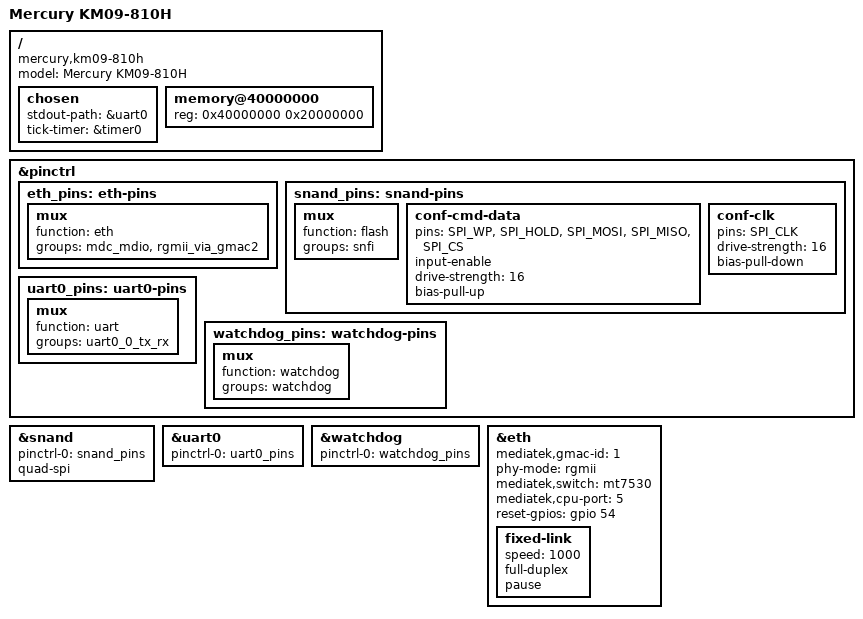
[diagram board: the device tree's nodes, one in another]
// SPDX-License-Identifier: GPL-2.0
/*
 * U-Boot device tree for the Mercury KM09-810H.
 * Configured with GMAC1 connected to internal MT7530 switch via RGMII (port@5 = CPU),
 * matching the stock bootloader ("GMAC1 Force link status enable" / "MT7530 Reset Completed").
 * GMAC0 is the WAN port behind an Aquantia PHY (2500base-x) and is NOT used here.
 */

/dts-v1/;
#include "mt7622.dtsi"
#include "mt7622-u-boot.dtsi"

/ {
	#address-cells = <1>;
	#size-cells = <1>;
	model = "Mercury KM09-810H";
	compatible = "mercury,km09-810h", "mediatek,mt7622";

	chosen {
		stdout-path = &uart0;
		tick-timer = &timer0;
	};

	memory@40000000 {
		device_type = "memory";
		reg = <0x40000000 0x20000000>;
	};
};

&pinctrl {
	eth_pins: eth-pins {
		mux {
			function = "eth";
			groups = "mdc_mdio", "rgmii_via_gmac2";
		};
	};

	snand_pins: snand-pins {
		mux {
			function = "flash";
			groups = "snfi";
		};

		conf-cmd-data {
			pins = "SPI_WP", "SPI_HOLD", "SPI_MOSI",
			       "SPI_MISO", "SPI_CS";
			input-enable;
			drive-strength = <16>;
			bias-pull-up;
		};

		conf-clk {
			pins = "SPI_CLK";
			drive-strength = <16>;
			bias-pull-down;
		};
	};

	uart0_pins: uart0-pins {
		mux {
			function = "uart";
			groups = "uart0_0_tx_rx";
		};
	};

	watchdog_pins: watchdog-pins {
		mux {
			function = "watchdog";
			groups = "watchdog";
		};
	};
};

&snand {
	pinctrl-names = "default";
	pinctrl-0 = <&snand_pins>;
	status = "okay";
	quad-spi;
};

&uart0 {
	pinctrl-names = "default";
	pinctrl-0 = <&uart0_pins>;
	status = "okay";
};

&watchdog {
	pinctrl-names = "default";
	pinctrl-0 = <&watchdog_pins>;
	status = "okay";
};

&eth {
	status = "okay";
	mediatek,gmac-id = <1>;
	phy-mode = "rgmii";
	mediatek,switch = "mt7530";
	/* MT7530 CPU link is on switch Port5 (vendor DTB: port@5 label "cpu") */
	mediatek,cpu-port = <5>;
	reset-gpios = <&gpio 54 GPIO_ACTIVE_HIGH>;

	fixed-link {
		speed = <1000>;
		full-duplex;
		pause;
	};
};
